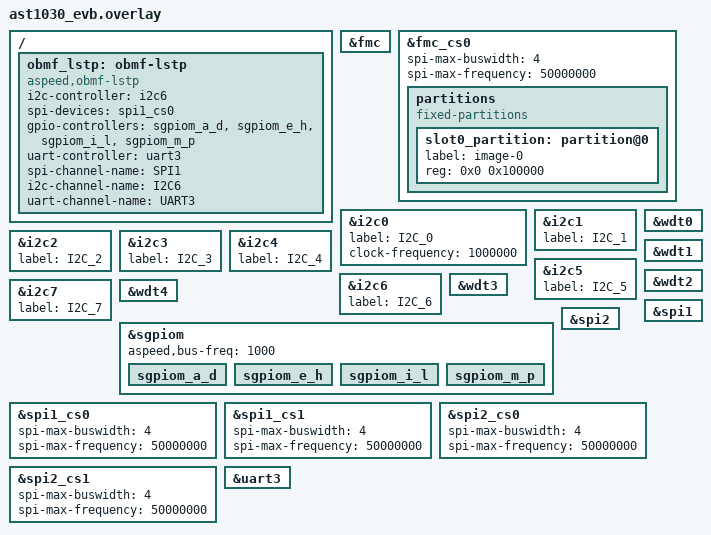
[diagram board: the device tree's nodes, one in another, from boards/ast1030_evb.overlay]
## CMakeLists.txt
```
# Copyright (c) 2026 ASPEED Technology Inc.
# SPDX-License-Identifier: Apache-2.0

cmake_minimum_required(VERSION 3.20.0)

find_package(Zephyr REQUIRED HINTS $ENV{ZEPHYR_BASE})
project(aspeed-obmf)

# Headers outside a source's own directory are included as "<dir>/<file>.h",
# so every cross-directory dependency is visible at the include site.
# lstp/ is the core and includes nothing outside itself.
target_include_directories(app PRIVATE src)

target_sources(app PRIVATE src/main.c)

# Root of the "obmf" command tree. Every other shell file adds its node to it,
# so it has to be there whenever the shell is.
target_sources_ifdef(CONFIG_SHELL app PRIVATE src/obmf_shell.c)

# The core and UART are always built. Other channel directories are built when
# their Kconfig option is set.
add_subdirectory(src/lstp)
add_subdirectory(src/uart)
add_subdirectory_ifdef(CONFIG_OBMF_LSTP_SPI_CHANNEL src/spi)
add_subdirectory_ifdef(CONFIG_OBMF_LSTP_I2C_CHANNEL src/i2c)
add_subdirectory_ifdef(CONFIG_OBMF_LSTP_GPIO_CHANNEL src/gpio)
add_subdirectory_ifdef(CONFIG_OBMF_LSTP_MTD_CLIENT src/mtd)
# AST1040-only bridge extension. CONFIG_ESPI alone is not an OBMF capability.
add_subdirectory_ifdef(CONFIG_OBMF_ESPI_BRIDGE src/espi)
```

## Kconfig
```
# SPDX-License-Identifier: Apache-2.0

config OBMF_ESPI_BRIDGE
	bool "OBMF eSPI bridge extension"
	default y
	depends on ESPI && ESPI_OOB_CHANNEL && ESPI_OOB_CHANNEL_RX_ASYNC
	depends on ESPI_TAF
	# The bridge calls the v2 OOB/perif API and registers a snoop callback.
	depends on ESPI_ASPEED_V2 && SNOOP_ASPEED
	depends on DT_HAS_ASPEED_ESPI_AST1040_ENABLED
	help
	  Enable the AST1040-only eSPI bridge services. The OOB bridge requires
	  asynchronous RX so it can be the channel's sole receive owner, and
	  the SAFS flash behind the MMIO window needs TAF. Direct LSTP
	  peripheral channels do not depend on this extension.

config OBMF_ESPI_MMIO
	bool "Expose the eSPI MMIO extension channel"
	default y
	depends on OBMF_ESPI_BRIDGE
	help
	  Add the MMIO channel described by the aspeed,obmf-lstp topology.

config OBMF_ESPI_MMIO_RESET
	bool "Allow the host to reboot the AST1040 over the MMIO channel"
	depends on OBMF_ESPI_MMIO
	select REBOOT
	help
	  Lets the host cold-reboot the AST1040 by writing offset 0xFFFFFFFC
	  with no data. There is no authorization: any USB host speaking LSTP
	  can trigger it. Rejected when disabled.

config OBMF_ESPI_MMIO_SAFS_WRITE
	bool "Allow the host to write the emulated SAFS flash over MMIO"
	depends on OBMF_ESPI_MMIO
	help
	  Lets the host load the RAM-backed SAFS flash that the eSPI host
	  boots from, through MMIO writes at offset 0x10000 and above. There
	  is no authorization: any USB host speaking LSTP can rewrite it.
	  Reads stay available; writes are rejected when disabled.

config OBMF_ESPI_UART_VUART
	bool "Bridge Host 0x3F8 through the hardware VUART0"
	depends on OBMF_ESPI_BRIDGE
	depends on $(dt_nodelabel_enabled,vuart0)
	default y
	help
	  Serve the LSTP UART channel from the AST1040 hardware VUART0 at
	  0x74c30000, which claims Host eSPI port 0x3F8 with a full
	  bidirectional FIFO on SerIRQ 4 (src/uart/lstp_uart_vuart.c).

	  Turning this off does not disable the UART channel -- it is always
	  exported. It selects src/uart/lstp_uart_plain.c instead, which
	  drives the ordinary UART named by the aspeed,obmf-lstp
	  uart-controller phandle (AST1030), or the shell backend when
	  CONFIG_OBMF_LSTP_UART_SHELL is set.

menu "OBMF LSTP peripheral channels"

config OBMF_LSTP_SPI_CHANNEL
	bool "Export the LSTP SPI channel"
	default y
	depends on FLASH_JESD216_API && FLASH_PAGE_LAYOUT
	help
	  Export the SPI flash listed in the aspeed,obmf-lstp topology
	  (spi-devices takes exactly one) as a read-only LSTP SPI channel.
	  The BMC's opcodes are served through the flash API (JEDEC ID, SFDP
	  and the 03h/13h/0Bh/0Ch reads); nothing is driven on the SPI bus
	  directly.

config OBMF_LSTP_MTD_CLIENT
	bool "Remote MTD client over LSTP SPI"
	default n
	depends on OBMF_LSTP_SPI_CHANNEL
	help
	  Enable firmware-initiated access to the peer's SPI flash and, with
	  CONFIG_SHELL, the "obmf mtd" commands.
	  Disabled by default because any shell user can program and erase the
	  peer's flash when this client is enabled.

config OBMF_LSTP_I2C_CHANNEL
	bool "Export the LSTP I2C channel"
	default y
	depends on I2C
	help
	  Export the I2C controller named by the aspeed,obmf-lstp topology as an
	  LSTP I2C channel. When disabled the BMC no longer registers an I2C
	  adapter for this device.

config OBMF_LSTP_UART_SHELL
	bool "Back the LSTP UART channel with shell commands"
	depends on SHELL && !OBMF_ESPI_UART_VUART
	help
	  Serve the LSTP UART channel with no UART behind it
	  (src/uart/lstp_uart_shell.c). What the BMC writes to its ttyLSTP is
	  kept for "obmf uart recv", and "obmf uart send" writes a
	  line back. The topology then needs no uart-controller.

config OBMF_LSTP_GPIO_CHANNEL
	bool "Export the LSTP GPIO channel"
	default y
	depends on GPIO
	help
	  Export the GPIO banks and eSPI virtual wires named by the
	  aspeed,obmf-lstp topology as an LSTP GPIO channel. When disabled no
	  GPIO IRQ events are forwarded and the BMC registers no gpiochip.

endmenu

source "Kconfig.zephyr"
```

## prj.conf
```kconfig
CONFIG_LOG=y
# CONFIG_LOG_MODE_IMMEDIATE=y
# CONFIG_LOG_DEFAULT_LEVEL=4
CONFIG_UART_CONSOLE_DEBUG_SERVER_HOOKS=y

# USB configuration
CONFIG_USB_DEVICE_STACK=y
# The IDs the NVIDIA OBMF/LSTP host driver binds to.
CONFIG_USB_DEVICE_MANUFACTURER="ASPEED"
CONFIG_USB_DEVICE_PRODUCT="OBMF-USB"
CONFIG_USB_DEVICE_VID=0x0955
CONFIG_USB_DEVICE_PID=0xcf11
CONFIG_USB_DEVICE_INITIALIZE_AT_BOOT=n
CONFIG_SHELL=y
CONFIG_SHELL_PROMPT_UART="ast1030-evb:~$ "
CONFIG_SHELL_STACK_SIZE=4096
CONFIG_SHELL_BACKEND_SERIAL_INIT_PRIORITY=99
CONFIG_SHELL_BACKEND_SERIAL_LOG_MESSAGE_QUEUE_TIMEOUT=-1
CONFIG_SHELL_BACKEND_SERIAL_LOG_MESSAGE_QUEUE_SIZE=1024
CONFIG_KERNEL_SHELL=y
# "select obmf <group>" makes a subtree the root, so a debug session types the leaf
# names only; alt+r returns to the top.
CONFIG_SHELL_CMDS_SELECT=y
CONFIG_REBOOT=y

CONFIG_UART_INTERRUPT_DRIVEN=y

# Every UART channel backend buffers through a ring_buf; the shell used to
# pull this in implicitly.
CONFIG_RING_BUFFER=y
```

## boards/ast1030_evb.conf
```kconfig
CONFIG_WATCHDOG=y
CONFIG_DYNAMIC_INTERRUPTS=y
CONFIG_GPIO_ASPEED_SGPIOM=y


CONFIG_USB_CDC_ACM=n
# For the NVIDIA OBMF USB host driver
CONFIG_USB_DEVICE_VID=0x0955
CONFIG_USB_DEVICE_PID=0xcf11
CONFIG_USB_DEVICE_MANUFACTURER="ASPEED"
CONFIG_USB_DEVICE_PRODUCT="OBMF-USB"
CONFIG_USB_DEVICE_SN="55661030"
CONFIG_USB_DEVICE_STACK=y
CONFIG_USB_REQUEST_BUFFER_SIZE=4096
# CONFIG_USB_DEVICE_LOG_LEVEL_OFF=y


CONFIG_MBEDTLS=n
CONFIG_MBEDTLS_SHA384=n
CONFIG_UART_ASPEED=y


CONFIG_USB_WORKQUEUE=y
```

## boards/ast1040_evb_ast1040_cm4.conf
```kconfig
CONFIG_WATCHDOG=y
CONFIG_DYNAMIC_INTERRUPTS=y

CONFIG_SPI=y
CONFIG_SPI_ASPEED=y
CONFIG_SPI_NOR=n
CONFIG_SPI_NOR_MULTI_DEV=y
CONFIG_SPI_DMA_SUPPORT_ASPEED=y

CONFIG_FLASH=y
CONFIG_FLASH_JESD216_API=y
CONFIG_FLASH_PAGE_LAYOUT=y
CONFIG_FLASH_MAP=y

CONFIG_I2C=y
CONFIG_I2C_ASPEED=y
CONFIG_I2C_TARGET=y


CONFIG_USB_CDC_ACM=n
# For the NVIDIA OBMF USB host driver
CONFIG_USB_DEVICE_VID=0x0955
CONFIG_USB_DEVICE_PID=0xcf11
CONFIG_USB_DEVICE_MANUFACTURER="ASPEED"
CONFIG_USB_DEVICE_PRODUCT="OBMF-USB"
CONFIG_USB_DEVICE_SN="55661040"
CONFIG_USB_DEVICE_STACK=y
CONFIG_USB_REQUEST_BUFFER_SIZE=4096
# CONFIG_USB_DEVICE_LOG_LEVEL_OFF=y

# The EVB has no host eSPI link (see ast1040_interposer for that), so it
# exports SPI, I2C and GPIO, and its UART channel drives uart0 (CON5).
CONFIG_OBMF_LSTP_SPI_CHANNEL=y
CONFIG_OBMF_LSTP_I2C_CHANNEL=y
CONFIG_OBMF_LSTP_GPIO_CHANNEL=y
CONFIG_UART_ASPEED=y

CONFIG_UART_NS16550_ACCESS_WORD_ONLY=y

CONFIG_SHELL_PROMPT_UART="ast1040-evb:~$ "

CONFIG_USB_WORKQUEUE=y

# The overlay disables &pwm and &tach; drop their drivers too.
CONFIG_PWM_ASPEED=n
CONFIG_TACH_ASPEED=n
```

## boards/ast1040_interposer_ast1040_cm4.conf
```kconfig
CONFIG_WATCHDOG=y
CONFIG_DYNAMIC_INTERRUPTS=y

CONFIG_ESPI=y
CONFIG_SNOOP_ASPEED=y
CONFIG_ESPI_ASPEED_V2=y
CONFIG_ESPI_PERIPHERAL_CHANNEL=y
CONFIG_ESPI_VWIRE_CHANNEL=y
CONFIG_ESPI_OOB_CHANNEL=y
CONFIG_ESPI_OOB_CHANNEL_RX_ASYNC=y
CONFIG_ESPI_FLASH_CHANNEL=y
CONFIG_ESPI_TAF=y

CONFIG_SPI=y
CONFIG_SPI_ASPEED=y
CONFIG_SPI_NOR=n
CONFIG_SPI_DMA_SUPPORT_ASPEED=y

CONFIG_FLASH=y
CONFIG_FLASH_JESD216_API=y
CONFIG_FLASH_PAGE_LAYOUT=y
CONFIG_FLASH_MAP=y
CONFIG_FLASH_SHELL=y

CONFIG_I2C=y
CONFIG_I2C_ASPEED=y
CONFIG_I2C_TARGET=y


CONFIG_USB_CDC_ACM=n
# For the NVIDIA OBMF USB host driver
CONFIG_USB_DEVICE_VID=0x0955
CONFIG_USB_DEVICE_PID=0xcf11
CONFIG_USB_DEVICE_MANUFACTURER="ASPEED"
CONFIG_USB_DEVICE_PRODUCT="OBMF-USB"
CONFIG_USB_DEVICE_SN="55661040"
CONFIG_USB_DEVICE_STACK=y
CONFIG_USB_REQUEST_BUFFER_SIZE=4096
# CONFIG_USB_DEVICE_LOG_LEVEL_OFF=y

# The interposer exports only the UART (host VUART) and MMIO channels.
CONFIG_OBMF_LSTP_SPI_CHANNEL=n
CONFIG_OBMF_LSTP_I2C_CHANNEL=n
CONFIG_OBMF_LSTP_GPIO_CHANNEL=n

CONFIG_UART_ASPEED=y
CONFIG_UART_NS16550_ACCESS_WORD_ONLY=y
CONFIG_OBMF_ESPI_UART_VUART=y
# The BMC loads the host's SAFS flash image over MMIO on this board.
CONFIG_OBMF_ESPI_MMIO_SAFS_WRITE=y

CONFIG_SHELL_PROMPT_UART="ast1040-interposer:~$ "

CONFIG_USB_WORKQUEUE=y

# The eSPI driver logs one line per peripheral-channel interrupt. During an MMBI
# transfer that is one line per memory cycle, which drowns the bridge's own
# traces and trips the log backend's drop path.
CONFIG_ESPI_LOG_LEVEL_WRN=y

# The overlay disables &pwm and &tach; drop their drivers too.
CONFIG_PWM_ASPEED=n
CONFIG_TACH_ASPEED=n
```

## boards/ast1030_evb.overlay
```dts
/ {
	obmf_lstp: obmf-lstp {
		compatible = "aspeed,obmf-lstp";
		i2c-controller = <&i2c6>;
		spi-devices = <&spi1_cs0>;
		gpio-controllers = <&sgpiom_a_d &sgpiom_e_h
				    &sgpiom_i_l &sgpiom_m_p>;
		uart-controller = <&uart3>;
		spi-channel-name = "SPI1";
		i2c-channel-name = "I2C6";
		uart-channel-name = "UART3";
		status = "okay";
	};
};

&fmc {
	status = "okay";
};

&fmc_cs0 {
	status = "okay";
	spi-max-buswidth = <4>;
	spi-max-frequency = <50000000>;

	partitions {
		compatible = "fixed-partitions";
		#address-cells = <1>;
		#size-cells = <1>;
		slot0_partition: partition@0 {
			label = "image-0";
			reg = <0x0 0x100000>;
		};
	};
};

&i2c0 {
	status = "okay";
	label = "I2C_0";
	clock-frequency = <1000000>;
};

&i2c1 {
	status = "okay";
	label = "I2C_1";
};

&i2c2 {
	status = "okay";
	label = "I2C_2";
};

&i2c3 {
	status = "okay";
	label = "I2C_3";
};

&i2c4 {
	status = "okay";
	label = "I2C_4";
};

&i2c5 {
	status = "okay";
	label = "I2C_5";
};

&i2c6 {
	status = "okay";
	label = "I2C_6";
};

&i2c7 {
	status = "okay";
	label = "I2C_7";
};

&wdt0 {
	status = "okay";
};

&wdt1 {
	status = "okay";
};

&wdt2 {
	status = "okay";
};

&wdt3 {
	status = "okay";
};

&wdt4 {
	status = "okay";
};

&sgpiom {
	status = "okay";
	aspeed,bus-freq = <1000>;

	sgpiom_a_d {
		status = "okay";
	};
	sgpiom_e_h {
		status = "okay";
	};
	sgpiom_i_l {
		status = "okay";
	};
	sgpiom_m_p {
		status = "okay";
	};
};

&spi1 {
	status = "okay";
};

&spi1_cs0 {
	status = "okay";
	spi-max-buswidth = <4>;
	spi-max-frequency = <50000000>;
};

&spi1_cs1 {
	status = "okay";
	spi-max-buswidth = <4>;
	spi-max-frequency = <50000000>;
};

&spi2 {
	status = "okay";
};

&spi2_cs0 {
	status = "okay";
	spi-max-buswidth = <4>;
	spi-max-frequency = <50000000>;
};

&spi2_cs1 {
	status = "okay";
	spi-max-buswidth = <4>;
	spi-max-frequency = <50000000>;
};

&uart3 {
	status = "okay";
};
```

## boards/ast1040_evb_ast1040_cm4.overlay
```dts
/ {
	obmf_lstp: obmf-lstp {
		compatible = "aspeed,obmf-lstp";
		spi-devices = <&spi0_cs0>;
		/* uart0 on F3/G5 reaches CON5 through J74 13-14/15-16 and U29. */
		uart-controller = <&uart0>;
		spi-channel-name = "SPI0";
		uart-channel-name = "UART0";
		status = "okay";
	};
};

&uart0 {
	pinctrl-0 = <pinctrl_uart0_default>;
	pinctrl-names = "default";
	clock-frequency = <1846153>;
	current-speed = <115200>;
	/*
	 * RX through UDMA: the 16-byte FIFO overruns whenever the ISR is held
	 * off for ~0.7 ms, the 1 KB DMA ring rides out ~89 ms.
	 */
	dma = <1>;
	status = "okay";
};

&i2c0 {
	status = "okay";
	/delete-node/ eeprom@40;
	/delete-node/ ipmb@60;
};

&tach {
	status = "disabled";
};

&spi1 {
	status = "disabled";
};

&spi1_cs0 {
	status = "disabled";
};

&spi1_cs1 {
	status = "disabled";
};

&i2c3 {
	status = "disabled";
};

&pwm {
	status = "disabled";
};

&spi0 {
	status = "okay";
};

&spi0_cs0 {
	status = "okay";
};

/* CS0's 256 MiB flash fills spi0's whole decode window; CS1 cannot map. */
&spi0_cs1 {
	status = "disabled";
};

/*
 * No SPI monitor on spi0: it filters the opcodes spi_nor_multi_dev needs at
 * probe (31h for the QE bit) and its address table only covers 64 MiB, so
 * reads past that come back as 0xdd.
 */
&spi0_filter {
	status = "disabled";
};

&spi0_spif {
	status = "disabled";
};

/* SGPIOM is unused on the EVB. */
/delete-node/ &sgpiom0;
/delete-node/ &sgpiom1;

&dram_ro_region {
	reg = <0x0 DT_SIZE_K(512)>;
};

/* Recreated rather than patched, so the unit address matches the new base. */
/delete-node/ &dram_rw_region;

/ {
	chosen {
		zephyr,sram = &dram_rw_region;
	};

	dram_rw_region: memory@80000 {
		device_type = "memory";
		reg = <0x80000 DT_SIZE_K(14336 - 512 - 512)>;
	};
};
```

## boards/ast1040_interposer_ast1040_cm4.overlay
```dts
/ {
	obmf_lstp: obmf-lstp {
		compatible = "aspeed,obmf-lstp";
		/*
		 * SPI, I2C and GPIO channels are off (see the .conf). i2c0, spi0
		 * and sgpiom0 stay enabled below for the local flash/i2c debug
		 * shells only; they are not exported to the BMC.
		 */
		uart-controller = <&vuart0>;
		uart-channel-name = "VUART0";

		espi-controller = <&espi0>;
		snoop-controller = <&snoop>;
		mmio-channel;
		ipmi-channel;
		status = "okay";
	};
};

&espi0 {
	status = "okay";
	flash-edaf-mode = <1>;
	perif-mcyc-enable;
	/*
	 * Host-side decode address for the peripheral memory window. It must
	 * equal the base the host's PCH programs into the eSPI LGMR BAR
	 * (Legacy Generic Memory Range) -- that is the only host address range
	 * forwarded to eSPI. Anything else, host DRAM included, is never
	 * claimed by this controller.
	 *
	 * PROVISIONAL. The BIOS prints the real value at boot as
	 * "EspiLgmrBaseAddr"; put that here. 0xEC000000 is only what
	 * MmbiV1Toolx64.efi compiles in as its default, and that default comes
	 * from a PCIe MMBI platform (its instance spans tens of MB, far past
	 * the 64 KiB an eSPI LGMR window can cover).
	 *
	 * Must stay aligned to perif-mcyc-size: the hardware decodes on
	 * addr & ~(size - 1).
	 */
	perif-mcyc-src-addr = <0x0 0xec000000>;
	perif-mcyc-size = <0x0 0x00010000>;
};

&snoop {
	status = "okay";
	port = <0x80>, <0x81>;
};

&i2c0 {
	status = "okay";
};

&vuart0 {
	status = "okay";
};

&tach {
	status = "disabled";
};

&spi1 {
	status = "disabled";
};

&spi1_cs0 {
	status = "disabled";
};

&spi1_cs1 {
	status = "disabled";
};

&i2c3 {
	status = "disabled";
};

&pwm {
	status = "disabled";
};

&spi0 {
	status = "okay";
};

&spi0_cs0 {
	status = "okay";
};

&spi0_cs1 {
	status = "okay";
};

&sgpiom0 {
	status = "okay";

	sgpiom0_0_31 {
		status = "okay";
	};

	sgpiom0_32_63 {
		status = "okay";
	};

	sgpiom0_64_95 {
		status = "okay";
	};

	sgpiom0_96_127 {
		status = "okay";
	};
};

&dram_ro_region {
	reg = <0x0 DT_SIZE_K(512)>;
};

/* Recreated rather than patched, so the unit address matches the new base. */
/delete-node/ &dram_rw_region;

/ {
	chosen {
		zephyr,sram = &dram_rw_region;
	};

	dram_rw_region: memory@80000 {
		device_type = "memory";
		reg = <0x80000 DT_SIZE_K(14336 - 512 - 512)>;
	};
};
```

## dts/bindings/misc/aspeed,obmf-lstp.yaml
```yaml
description: ASPEED OBMF LSTP backend topology

compatible: "aspeed,obmf-lstp"

include: base.yaml

properties:
# The core and UART are always built. Other channel directories are built when
# their Kconfig option is set.
# lstp/lstp_backend.h checks fields required by the enabled backends.
  i2c-controller:
    type: phandle
    description: |
      I2C controller exported by the LSTP I2C channel. Required with
      CONFIG_OBMF_LSTP_I2C_CHANNEL.

  spi-devices:
    type: phandles
    description: |
      The one SPI flash exported as LSTP chip-select 0; list exactly one
      phandle. Required with CONFIG_OBMF_LSTP_SPI_CHANNEL.

  gpio-controllers:
    type: phandles
    description: |
      GPIO banks ordered by the LSTP logical GPIO index. Required with
      CONFIG_OBMF_LSTP_GPIO_CHANNEL.

  uart-controller:
    type: phandle
    description: |
      UART device exported by the LSTP UART channel: the hardware VUART with
      CONFIG_OBMF_ESPI_UART_VUART, otherwise a plain UART. Not needed when
      CONFIG_OBMF_LSTP_UART_SHELL backs the channel with shell commands.

  spi-channel-name:
    type: string
    default: "SPI"

  i2c-channel-name:
    type: string
    default: "I2C"

  uart-channel-name:
    type: string
    default: "UART"

  espi-controller:
    type: phandle
    description: eSPI controller used by the AST1040 bridge. Required with
      CONFIG_OBMF_ESPI_BRIDGE.

  snoop-controller:
    type: phandle
    description: eSPI snoop controller used by the AST1040 bridge. Required
      with CONFIG_OBMF_ESPI_BRIDGE.

  gpio-input-lines:
    type: array
    description: |
      LSTP GPIO indices reported to the BMC as inputs that can take an IRQ
      configuration. They are made inputs at init.

  gpio-output-lines:
    type: array
    description: |
      LSTP GPIO indices the BMC may drive. This is an allow-list: the
      gpio-controllers banks export whole 32-pin ports, and a pin left off
      this list (a pinmuxed UART/I2C pin, a strap, a reset or power enable)
      is reported as an input and SetValue on it is rejected. A pin on neither
      list is never reconfigured; gpio-input-lines pins are made inputs at init.
      A pin must not be in both lists.

  vwire-gpio-base:
    type: int
    default: 0
    description: First logical GPIO index reserved for eSPI virtual wires

  vwire-gpio-count:
    type: int
    default: 0
    description: Number of eSPI virtual wires appended to the GPIO channel

  mmio-channel:
    type: boolean
    description: Export the AST1040 eSPI MMIO extension channel
```

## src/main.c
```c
/*
 * Copyright (c) 2026 ASPEED Technology Inc.
 *
 * SPDX-License-Identifier: Apache-2.0
 */

#include <zephyr/kernel.h>
#include <zephyr/logging/log.h>
#include <zephyr/usb/usb_device.h>
#include "lstp/lstp_router.h"
#include "lstp/lstp_usb.h"

LOG_MODULE_REGISTER(main, LOG_LEVEL_INF);

int main(void)
{
	LOG_INF("Starting aspeed-obmf application");

	/* Also brings up every exported channel. */
	lstp_router_init();

	int ret = lstp_usb_init();
	if (ret != 0) {
		LOG_ERR("Failed to initialize USB subsystem: %d", ret);
		return ret;
	}

	LOG_INF("aspeed-obmf application running");

	while (1) {
		k_sleep(K_SECONDS(1));
	}

	return 0;
}
```

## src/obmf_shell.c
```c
/*
 * Copyright (c) 2026 ASPEED Technology Inc.
 *
 * SPDX-License-Identifier: Apache-2.0
 */

#include <zephyr/shell/shell.h>
#include <zephyr/sys/util.h>

#include "gpio/lstp_gpio.h"
#include "uart/lstp_uart.h"
#include "lstp/lstp_usb.h"

static int cmd_lstp_stats(const struct shell *sh, size_t argc, char **argv)
{
	struct lstp_uart_stats uart;
	struct lstp_usb_stats usb;

	ARG_UNUSED(argc);
	ARG_UNUSED(argv);

	lstp_uart_get_stats(&uart);
	lstp_usb_get_stats(&usb);

	shell_print(sh, "UART drops (bytes)");
	shell_print(sh, "  RX ring overflow: %u", uart.rx_dropped_bytes);
	shell_print(sh, "  RX FIFO overruns: %u  (LSR.OE events, not bytes)",
		    uart.rx_fifo_overruns);
	shell_print(sh, "  TX dropped      : %u  (host not draining VUART)",
		    uart.tx_dropped_bytes);
	shell_print(sh, "  TX NAK events   : %u  (host-to-UART writes, backend buffer full)",
		    uart.tx_nak_events);
	shell_print(sh, "  RX fwd dropped  : %u  (bytes, no host or host reset)",
		    uart.rx_forward_dropped_bytes);
	shell_print(sh, "USB transport");
	shell_print(sh, "  response drops  : %u", usb.response_drops);
	shell_print(sh, "  event drops     : %u  (USB event queue full, caller may retry)",
		    usb.event_drops);
	shell_print(sh, "  rx drops        : %u", usb.rx_drops);
	shell_print(sh, "  write errors    : %u", usb.write_errors);
	shell_print(sh, "  tx queue peak   : %u", usb.tx_high_water);
	if (IS_ENABLED(CONFIG_OBMF_LSTP_GPIO_CHANNEL)) {
		shell_print(sh, "LSTP GPIO");
		shell_print(sh, "  gpio irq drops  : %u", lstp_gpio_get_irq_drops());
		shell_print(sh, "  gpio event drops: %u  (sent but rejected by USB)",
			    lstp_gpio_get_event_drops());
	}

	return 0;
}

SHELL_SUBCMD_SET_CREATE(sub_obmf, (obmf));

SHELL_SUBCMD_ADD((obmf), stats, NULL, "Show LSTP drop/queue counters",
		 cmd_lstp_stats, 1, 0);

SHELL_CMD_REGISTER(obmf, &sub_obmf, "OBMF demo commands ('select obmf <node>' to stay inside one)",
		   NULL);
```
